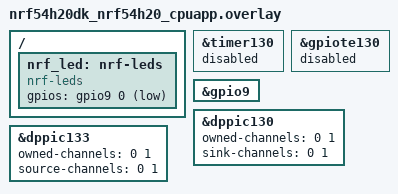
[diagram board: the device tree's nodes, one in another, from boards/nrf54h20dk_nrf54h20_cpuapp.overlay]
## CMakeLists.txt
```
cmake_minimum_required(VERSION 3.20.0)

find_package(Zephyr REQUIRED HINTS $ENV{ZEPHYR_BASE})
project(dimmer)

FILE(GLOB app_sources src/*.c)
# NORDIC SDK APP START
target_sources(app PRIVATE ${app_sources})
# NORDIC SDK APP END
```

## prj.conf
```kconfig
CONFIG_LOG=y
CONFIG_LED_NRF=y

CONFIG_NRFX_TIMER130=y
CONFIG_GPIO=n
CONFIG_NRFX_DPPI=y
CONFIG_NRFX_GPIOTE130=y
CONFIG_PM_DEVICE=y
```

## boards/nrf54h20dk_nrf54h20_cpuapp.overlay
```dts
&timer130 {
	status = "reserved";
};

&gpiote130 {
	status = "reserved";
};

&gpio9 {
	status = "okay";
};

&dppic130 {
	owned-channels = <0 1>;
	sink-channels = <0 1>;
	status = "okay";
};

&dppic133 {
	owned-channels = <0 1>;
	source-channels = <0 1>;
	status = "okay";
};

/ {
	nrf_led:nrf-leds {
		compatible = "nrf-leds";
		status = "okay";
		gpios = <&gpio9 0 GPIO_ACTIVE_LOW>;
	};
};
```

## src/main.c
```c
/*
 * Copyright (c) 2024 Nordic Semiconductor ASA.
 *
 * SPDX-License-Identifier: LicenseRef-Nordic-5-Clause
 */

#include <stdio.h>
#include <zephyr/drivers/led.h>
#include <zephyr/kernel.h>
#include <zephyr/device.h>
#include <zephyr/pm/device.h>
#include <zephyr/sys/util.h>
#include <inttypes.h>



int main(void)
{
	uint8_t dim_value = 0;
	const struct device *led_nrf;
	led_nrf = DEVICE_DT_GET(DT_NODELABEL(nrf_led));
	while (dim_value < 100)
	{
		led_set_brightness(led_nrf, 0, dim_value++);
		k_sleep(K_MSEC(50));
	}


	pm_device_action_run(led_nrf, PM_DEVICE_ACTION_SUSPEND);

	return 0;
}
```
